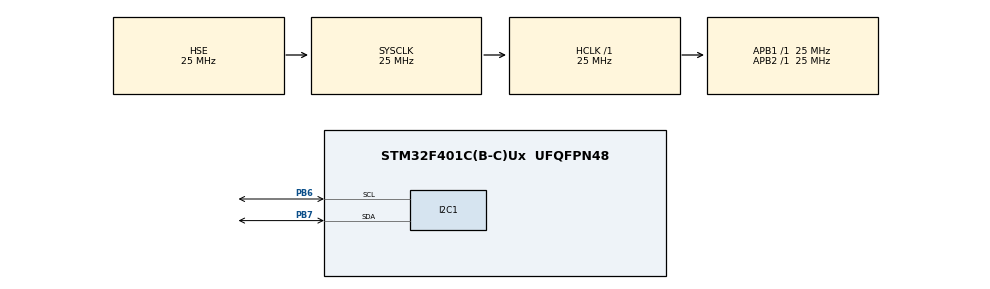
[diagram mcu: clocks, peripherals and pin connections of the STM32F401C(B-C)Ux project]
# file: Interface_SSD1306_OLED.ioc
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I2C1.I2C_Mode=I2C_Fast
Mcu.Family=STM32F4
Mcu.Name=STM32F401C(B-C)Ux
Mcu.Package=UFQFPN48
NVIC.PriorityGroup=NVIC_PRIORITYGROUP_4
PA13.Mode=Serial_Wire
PA13.Signal=SYS_JTMS-SWDIO
PA14.Mode=Serial_Wire
PA14.Signal=SYS_JTCK-SWCLK
PB6.Mode=I2C
PB6.Signal=I2C1_SCL
PB7.Mode=I2C
PB7.Signal=I2C1_SDA
PH0\ -\ OSC_IN.Mode=HSE-External-Oscillator
PH0\ -\ OSC_IN.Signal=RCC_OSC_IN
PH1\ -\ OSC_OUT.Mode=HSE-External-Oscillator
PH1\ -\ OSC_OUT.Signal=RCC_OSC_OUT
ProjectManager.HeapSize=0x200
ProjectManager.StackSize=0x400
ProjectManager.TargetToolchain=MDK-ARM V5.32
RCC.48MHZClocksFreq_Value=75000000
RCC.AHBFreq_Value=25000000
RCC.APB1Freq_Value=25000000
RCC.APB1TimFreq_Value=25000000
RCC.APB2Freq_Value=25000000
RCC.APB2TimFreq_Value=25000000
RCC.CortexFreq_Value=25000000
RCC.HCLKFreq_Value=25000000
RCC.HSE_VALUE=25000000
RCC.HSI_VALUE=16000000
RCC.LSE_VALUE=32768
RCC.PLLSourceVirtual=RCC_PLLSOURCE_HSE
RCC.SYSCLKFreq_VALUE=25000000
RCC.SYSCLKSource=RCC_SYSCLKSOURCE_HSE
RCC.VCOOutputFreq_Value=300000000
board=custom

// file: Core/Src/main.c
/* USER CODE BEGIN Header */
/**
  ******************************************************************************
  * @file           : main.c
  * @brief          : Main program body
  ******************************************************************************
  * @attention
  *
  * Copyright (c) 2024 STMicroelectronics.
  * All rights reserved.
  *
  * This software is licensed under terms that can be found in the LICENSE file
  * in the root directory of this software component.
  * If no LICENSE file comes with this software, it is provided AS-IS.
  *
  ******************************************************************************
  */
/* USER CODE END Header */
#include "main.h"

/* USER CODE BEGIN Includes */
#include "stdio.h"

#include "SSD1306_OLED/ssd1306.h"
#include "SSD1306_OLED/fonts.h"
#include "SSD1306_OLED/bitmap.h"
#include "SSD1306_OLED/horse_anim.h"

/* USER CODE END Includes */

I2C_HandleTypeDef hi2c1;

void SystemClock_Config(void);
static void MX_GPIO_Init(void);
static void MX_I2C1_Init(void);

int main(void)
{

  /* MCU Configuration--------------------------------------------------------*/

  /* Reset of all peripherals, Initializes the Flash interface and the Systick. */
  HAL_Init();

  /* Configure the system clock */
  SystemClock_Config();

  /* Initialize all configured peripherals */
  MX_GPIO_Init();
  MX_I2C1_Init();
  /* USER CODE BEGIN 2 */
	int16_t xx = 0;
	int16_t yy = 10;
	int width = 125;
	int cnt = 0;

	 // Example integer
    int number = 12345;

    // Buffer to hold the converted string
    char buffer[10];

    // Convert the integer to a string
    sprintf(buffer, "%d", number);

	int color = SSD1306_COLOR_WHITE;
	int delay = 0;
	SSD1306_Init (); // initialise the display
	SSD1306_GotoXY (0, 0); // goto 10, 10
	SSD1306_Puts ("Rajib Hasan", &Font_11x18, 1); // print Hello
	SSD1306_GotoXY (10, 30);
	SSD1306_Puts ("WORLD !!", &Font_16x26, 1);
	SSD1306_UpdateScreen(); // update screen
	HAL_Delay(2000);
	SSD1306_Clear();
	HAL_Delay(200);
  /* USER CODE END 2 */

  /* Infinite loop */
  /* USER CODE BEGIN WHILE */
  while (1)
  {
		/*
		cnt++;
		sprintf(buffer, "%d", cnt);
		// Clear the screen
    //SSD1306_Clear();

    // Set cursor to (x:0, y:0)
    SSD1306_GotoXY(30, 20);

    // Display the string
    SSD1306_Puts(buffer, &Font_16x26, SSD1306_COLOR_WHITE);

    // Update the screen
    SSD1306_UpdateScreen();
		HAL_Delay(100);
		while(1){
			for(int i = 0; i<100; i++){
			SSD1306_Clear();
			sprintf(buffer, "%d", i);
			SSD1306_GotoXY(30, 20);
			SSD1306_Puts(buffer, &Font_16x26, SSD1306_COLOR_WHITE);
			SSD1306_UpdateScreen();
			HAL_Delay(100);
		}
		for(int i = 100; i>1; i--){
			SSD1306_Clear();
			sprintf(buffer, "%d", i);
			SSD1306_GotoXY(30, 20);
			SSD1306_Puts(buffer, &Font_16x26, SSD1306_COLOR_WHITE);
			SSD1306_UpdateScreen();
			HAL_Delay(100);
		}

		}
		*/

    /* USER CODE END WHILE */

    /* USER CODE BEGIN 3 */
		SSD1306_Clear();
	  SSD1306_DrawBitmap(xx, yy,horse1,width,64, color);
	  SSD1306_UpdateScreen();
		HAL_Delay(delay);

	  SSD1306_Clear();
	  SSD1306_DrawBitmap(xx , yy,horse2,width,64, color);
	  SSD1306_UpdateScreen();
		HAL_Delay(delay);

	  SSD1306_Clear();
	  SSD1306_DrawBitmap(xx, yy,horse3,width,64,color);
	  SSD1306_UpdateScreen();
		HAL_Delay(delay);

	  SSD1306_Clear();
	  SSD1306_DrawBitmap(xx, yy,horse4,width,64,color);
	  SSD1306_UpdateScreen();
		HAL_Delay(delay);

	  SSD1306_Clear();
	  SSD1306_DrawBitmap(xx, yy,horse5,width,64, color);
	  SSD1306_UpdateScreen();
		HAL_Delay(delay);

	  SSD1306_Clear();
	  SSD1306_DrawBitmap(xx, yy,horse6,width,64, color);
	  SSD1306_UpdateScreen();
		HAL_Delay(delay);

	  SSD1306_Clear();
	  SSD1306_DrawBitmap(xx, yy,horse7,width,64, color);
	  SSD1306_UpdateScreen();
		HAL_Delay(delay);

	  SSD1306_Clear();
	  SSD1306_DrawBitmap(xx, yy,horse8,width,64, color);
	  SSD1306_UpdateScreen();
		HAL_Delay(delay);

	  SSD1306_Clear();
	  SSD1306_DrawBitmap(xx, yy,horse9,width,64, color);
	  SSD1306_UpdateScreen();
		HAL_Delay(delay);

	  SSD1306_Clear();
	  SSD1306_DrawBitmap(xx, yy,horse10,width,64, color);
	  SSD1306_UpdateScreen();
		HAL_Delay(delay);
  }
  /* USER CODE END 3 */
}

void SystemClock_Config(void)
{
  RCC_OscInitTypeDef RCC_OscInitStruct = {0};
  RCC_ClkInitTypeDef RCC_ClkInitStruct = {0};

  /** Configure the main internal regulator output voltage
  */
  __HAL_RCC_PWR_CLK_ENABLE();
  __HAL_PWR_VOLTAGESCALING_CONFIG(PWR_REGULATOR_VOLTAGE_SCALE2);

  /** Initializes the RCC Oscillators according to the specified parameters
  * in the RCC_OscInitTypeDef structure.
  */
  RCC_OscInitStruct.OscillatorType = RCC_OSCILLATORTYPE_HSE;
  RCC_OscInitStruct.HSEState = RCC_HSE_ON;
  RCC_OscInitStruct.PLL.PLLState = RCC_PLL_NONE;
  if (HAL_RCC_OscConfig(&RCC_OscInitStruct) != HAL_OK)
  {
    Error_Handler();
  }

  /** Initializes the CPU, AHB and APB buses clocks
  */
  RCC_ClkInitStruct.ClockType = RCC_CLOCKTYPE_HCLK|RCC_CLOCKTYPE_SYSCLK
                              |RCC_CLOCKTYPE_PCLK1|RCC_CLOCKTYPE_PCLK2;
  RCC_ClkInitStruct.SYSCLKSource = RCC_SYSCLKSOURCE_HSE;
  RCC_ClkInitStruct.AHBCLKDivider = RCC_SYSCLK_DIV1;
  RCC_ClkInitStruct.APB1CLKDivider = RCC_HCLK_DIV1;
  RCC_ClkInitStruct.APB2CLKDivider = RCC_HCLK_DIV1;

  if (HAL_RCC_ClockConfig(&RCC_ClkInitStruct, FLASH_LATENCY_0) != HAL_OK)
  {
    Error_Handler();
  }
}

static void MX_I2C1_Init(void)
{

  hi2c1.Instance = I2C1;
  hi2c1.Init.ClockSpeed = 400000;
  hi2c1.Init.DutyCycle = I2C_DUTYCYCLE_2;
  hi2c1.Init.OwnAddress1 = 0;
  hi2c1.Init.AddressingMode = I2C_ADDRESSINGMODE_7BIT;
  hi2c1.Init.DualAddressMode = I2C_DUALADDRESS_DISABLE;
  hi2c1.Init.OwnAddress2 = 0;
  hi2c1.Init.GeneralCallMode = I2C_GENERALCALL_DISABLE;
  hi2c1.Init.NoStretchMode = I2C_NOSTRETCH_DISABLE;
  if (HAL_I2C_Init(&hi2c1) != HAL_OK)
  {
    Error_Handler();
  }

}

static void MX_GPIO_Init(void)
{

  /* GPIO Ports Clock Enable */
  __HAL_RCC_GPIOH_CLK_ENABLE();
  __HAL_RCC_GPIOA_CLK_ENABLE();
  __HAL_RCC_GPIOB_CLK_ENABLE();

}

void Error_Handler(void)
{
  __disable_irq();
  while (1)
  {
  }
}
